AUTOSAR XML (schema 00052)
package /katech/AdaptiveApplicationSwComponentTypes
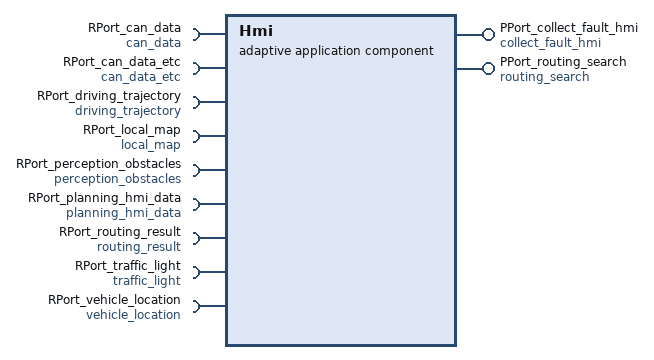
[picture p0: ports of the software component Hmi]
  adaptive application sw component type Hmi
    provide port PPort_collect_fault_hmi: provided-interface=collect_fault_hmi
    provide port PPort_routing_search: provided-interface=routing_search
    9 x require port:
      RPort_can_data: required-interface=can_data
      RPort_can_data_etc: required-interface=can_data_etc
      RPort_driving_trajectory: required-interface=driving_trajectory
      RPort_local_map: required-interface=local_map
      RPort_perception_obstacles: required-interface=perception_obstacles
      RPort_planning_hmi_data: required-interface=planning_hmi_data
      RPort_routing_result: required-interface=routing_result
      RPort_traffic_light: required-interface=traffic_light
      RPort_vehicle_location: required-interface=vehicle_location
package /katech/Executables
  executable Hmi: category=APPLICATION_LEVEL, minimum-timer-granularity=1000
    root sw component prototype Hmi: application-type=Hmi
